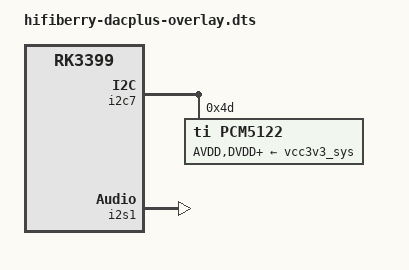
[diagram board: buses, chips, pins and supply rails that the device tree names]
/dts-v1/;
/plugin/;

/ {
	compatible = "rockchip,rk3399";

	fragment@0 {
		target-path = "/";
		__overlay__ {
			dacpro_osc: dacpro_osc {
				compatible = "hifiberry,dacpro-clk";
				#clock-cells = <0>;
			};
		};
	};

	fragment@1 {
		target = <&i2c7>;
		__overlay__ {
			#address-cells = <1>;
			#size-cells = <0>;
			status = "okay";
			
			pcm5122@4d {
				#sound-dai-cells = <0>;
				compatible = "ti,pcm5122";
				reg = <0x4d>;
				clocks = <&dacpro_osc>;
				AVDD-supply = <&vcc3v3_sys>;
				DVDD-supply = <&vcc3v3_sys>;
				CPVDD-supply = <&vcc3v3_sys>;
				status = "okay";
			};
		};
	};

	fragment@2 {
		target-path = "/sound-ext-card";
			
		 __overlay__ {
			compatible = "hifiberry,hifiberry-dacplus";
			i2s-controller = <&i2s1>;
			status = "okay";
		};
	};

	fragment@3 {
		target = <&i2s1>;
		__overlay__ {
			status = "okay";
			#sound-dai-cells = <0>;
		};
	};

	__overrides__ {
		24db_digital_gain =
			<&sound_ext_card>,"hifiberry,24db_digital_gain?";
		slave = <&sound_ext_card>,"hifiberry-dacplus,slave?";
	};
};
